# LPC845 register map
Vendor: NXP Semiconductors; Series: LPC; File version: 1.6
CPU: CM0PLUS r0p0, little endian, no MPU, no FPU, VTOR, 2 interrupt priority bits
Registers are 32-bit, read-write, reset 0x0 unless marked. A register's access mark holds for its fields unless they carry their own. Offsets are from the block's base; [hi:lo] are bit positions.

## MTB_SFR — LPC84x Micro Trace Buffer
Base 0x5000C000
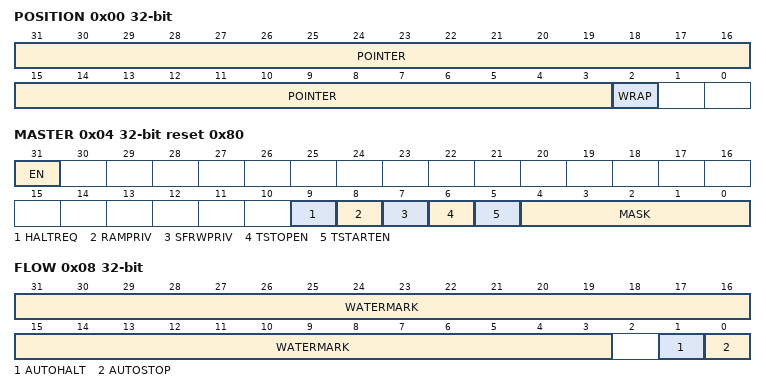
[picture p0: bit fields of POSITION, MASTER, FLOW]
0x00 POSITION reset not defined
  [31:3] POINTER — Trace packet location pointer. Because a packet consists of two words, the POINTER field is the location of the first word of a packet. This field contains bits [31:3] of the address, in the SRAM, where the next trace packet will be written. The field points to an unused location and is automatically incremented. A debug agent can calculate the system address, on the AHB-Lite bus, of the SRAM location pointed to by the POSITION register using the following equation: system address = BASE + ((P + (2AWIDTH - (BASE MOD 2AWIDTH))) MOD 2AWIDTH). Where P = POSITION AND 0xFFFF_FFF8. Where BASE is the BASE register value
  [2] WRAP — This bit is set to 1 automatically when the POINTER value wraps as determined by the MASTER.MASK field in the MASTER Trace Control Register.
0x04 MASTER reset 0x80 (reset mask 0x800003E0)
  [31] EN — Main trace enable bit. When this bit is 1 trace data is written into the SRAM memory location addressed by POSITION.POINTER. The POSITION.POINTER value auto increments after the trace data packet is written. The EN bit can be automatically set to 0 using the FLOW.WATERMARK field and the FLOW.AUTOSTOP bit. The EN bit is automatically set to 1 if the TSTARTEN bit is 1 and the TSTART signal is HIGH. The EN bit is automatically set to 0 if TSTOPEN bit is 1 and the TSTOP signal is HIGH.
  [9] HALTREQ — Halt request bit. This bit is connected to the halt request signal of the trace logic, EDBGRQ. When HALTREQ is set to 1, EDBGRQ is asserted if DBGEN is also HIGH. The HALTREQ bit can be automatically set to 1 using the FLOW.WATERMARK field.
  [8] RAMPRIV — SRAM Privilege bit. If this bit is 0, then User or Privileged AHB-Lite read and write accesses to the SRAM are permitted. If this bit is 1, then only Privileged AHB-Lite read and write accesses to the SRAM are permitted and User accesses are RAZ/WI. The HPROT[1] signal determines if an access is User or Privileged.
  [7] SFRWPRIV — Special Function Register Write Privilege bit. If this bit is 0, then User or Privileged AHB-Lite read and write accesses to the Special Function Registers are permitted. If this bit is 1, then only Privileged write accesses are permitted and User write accesses are ignored. The HPROT[1] signal determines if an access is User or Privileged.
  [6] TSTOPEN — Trace stop input enable. If this bit is 1 and the TSTOP signal is HIGH, then the EN bit is set to 0. If a trace packet is being written to memory, the write is completed before tracing is stopped.
  [5] TSTARTEN — Trace start input enable. If this bit is 1 and the TSTART signal is HIGH, then the EN bit is set to 1. Tracing continues until a stop condition occurs.
  [4:0] MASK — This value determines the maximum size of the trace buffer in SRAM. It specifies the most-significant bit of the POSITION.POINTER field that can be updated by automatic increment. If the trace tries to advance past this power of two, the POSITION.WRAP bit is set to 1, the POSITION.POINTER[MASK:0] bits are set to zero, and the POSITION.POINTER[AWIDTH-4:MASK+1] bits remain unchanged. This field causes the trace packet information to be stored in a circular buffer of size 2(MASK+4) bytes, that can be positioned in memory at multiples of this size. Valid values of this field are zero to AWIDTH-4. Values greater than the maximum have the same effect as the maximum.
0x08 FLOW (reset mask 0x3)
  [31:3] WATERMARK — WATERMARK value. This field contains an address in the same format as the POSITION.POINTER field. When the POSITION.POINTER matches the WATERMARK field value, actions defined by the AUTOHALT and AUTOSTOP bits are performed.
  [1] AUTOHALT — If this bit is 1 and WATERMARK is equal to POSITION.POINTER, then the MASTER.HALTREQ bit is automatically set to 1. If the DBGEN signal is HIGH, the MTB asserts this halt request to the Cortex-M0+ processor by asserting the EDBGRQ signal.
  [0] AUTOSTOP — If this bit is 1 and WATERMARK is equal to POSITION.POINTER, then the MASTER.EN bit is automatically set to 0. This stops tracing.
0x0C BASE ro reset not defined — Indicates where the SRAM is located in the processor memory map. This register is provided to enable auto discovery of the MTB SRAM location, by a debug agent.
  [31:0] BASE — The value provided is the value of the SRAMBASEADDR[31:0] signal.
